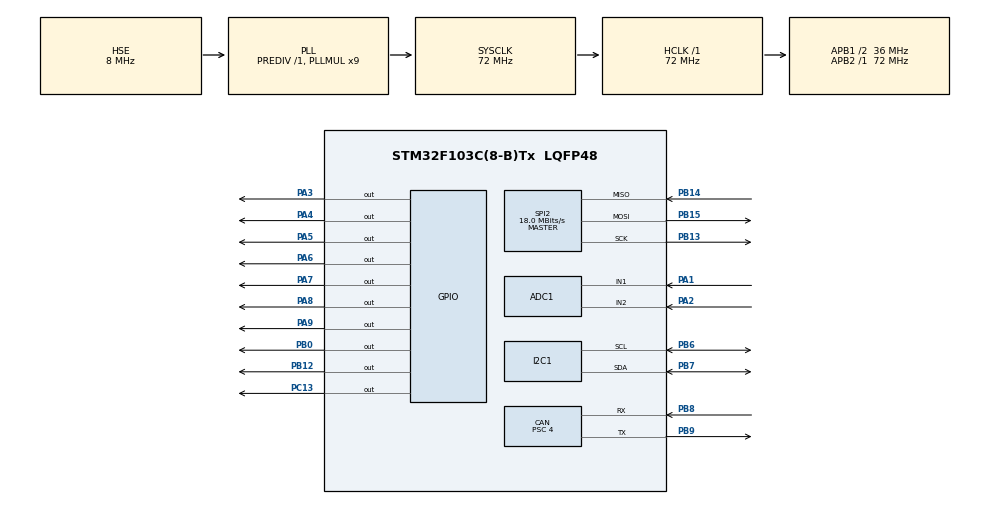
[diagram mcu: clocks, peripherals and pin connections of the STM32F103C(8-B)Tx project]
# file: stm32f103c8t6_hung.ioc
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ADC1.Channel-0\#ChannelRegularConversion=ADC_CHANNEL_1
ADC1.NbrOfConversionFlag=1
ADC1.Rank-0\#ChannelRegularConversion=1
ADC1.SamplingTime-0\#ChannelRegularConversion=ADC_SAMPLETIME_1CYCLE_5
ADC1.master=1
CAN.ABOM=ENABLE
CAN.AWUM=ENABLE
CAN.BS1=CAN_BS1_15TQ
CAN.BS2=CAN_BS2_2TQ
CAN.CalculateBaudRate=500000
CAN.CalculateTimeBit=2000
CAN.CalculateTimeQuantum=111.11111111111111
CAN.Prescaler=4
IWDG.Prescaler=IWDG_PRESCALER_64
IWDG.Reload=625
Mcu.Family=STM32F1
Mcu.Name=STM32F103C(8-B)Tx
Mcu.Package=LQFP48
NVIC.ADC1_2_IRQn=true\:0\:0\:false\:false\:true\:true\:true\:true
NVIC.PriorityGroup=NVIC_PRIORITYGROUP_4
NVIC.USB_LP_CAN1_RX0_IRQn=true\:0\:0\:false\:false\:true\:true\:true\:true
PA1.Signal=ADCx_IN1
PA13.Mode=Serial_Wire
PA13.Signal=SYS_JTMS-SWDIO
PA14.Mode=Serial_Wire
PA14.Signal=SYS_JTCK-SWCLK
PA2.Signal=ADCx_IN2
PA3.Signal=GPIO_Output
PA4.Signal=GPIO_Output
PA5.Signal=GPIO_Output
PA6.Signal=GPIO_Output
PA7.Signal=GPIO_Output
PA8.Signal=GPIO_Output
PA9.Signal=GPIO_Output
PB0.Signal=GPIO_Output
PB12.Signal=GPIO_Output
PB13.Mode=Full_Duplex_Master
PB13.Signal=SPI2_SCK
PB14.Mode=Full_Duplex_Master
PB14.Signal=SPI2_MISO
PB15.Mode=Full_Duplex_Master
PB15.Signal=SPI2_MOSI
PB6.Mode=I2C
PB6.Signal=I2C1_SCL
PB7.Mode=I2C
PB7.Signal=I2C1_SDA
PB8.GPIO_PuPd=GPIO_PULLUP
PB8.Mode=CAN_Activate
PB8.Signal=CAN_RX
PB9.Mode=CAN_Activate
PB9.Signal=CAN_TX
PC13-TAMPER-RTC.Signal=GPIO_Output
PC14-OSC32_IN.Mode=LSE-External-Oscillator
PC14-OSC32_IN.Signal=RCC_OSC32_IN
PC15-OSC32_OUT.Mode=LSE-External-Oscillator
PC15-OSC32_OUT.Signal=RCC_OSC32_OUT
PD0-OSC_IN.Mode=HSE-External-Oscillator
PD0-OSC_IN.Signal=RCC_OSC_IN
PD1-OSC_OUT.Mode=HSE-External-Oscillator
PD1-OSC_OUT.Signal=RCC_OSC_OUT
ProjectManager.HeapSize=0x200
ProjectManager.StackSize=0x400
ProjectManager.TargetToolchain=STM32CubeIDE
RCC.ADCPresc=RCC_ADCPCLK2_DIV6
RCC.AHBFreq_Value=72000000
RCC.APB1CLKDivider=RCC_HCLK_DIV2
RCC.APB1Freq_Value=36000000
RCC.APB1TimFreq_Value=72000000
RCC.APB2Freq_Value=72000000
RCC.APB2TimFreq_Value=72000000
RCC.HCLKFreq_Value=72000000
RCC.PLLMUL=RCC_PLL_MUL9
RCC.PLLSourceVirtual=RCC_PLLSOURCE_HSE
RCC.SYSCLKFreq_VALUE=72000000
RCC.SYSCLKSource=RCC_SYSCLKSOURCE_PLLCLK
RCC.USBFreq_Value=72000000
SH.ADCx_IN1.0=ADC1_IN1,IN1
SH.ADCx_IN2.0=ADC1_IN2,IN2
SPI2.CalculateBaudRate=18.0 MBits/s
SPI2.Direction=SPI_DIRECTION_2LINES
SPI2.Mode=SPI_MODE_MASTER
SPI2.VirtualType=VM_MASTER
VP_ADC1_TempSens_Input.Mode=IN-TempSens
VP_IWDG_VS_IWDG.Mode=IWDG_Activate
board=custom

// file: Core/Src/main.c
/* USER CODE BEGIN Header */
/* USER CODE END Header */
#include "main.h"
#include"i2c_drive.h"
#include <stdio.h>
#include<can_drive.h>
#include<uart_drive.h>
#include "mgr_com.h"
#include "il_para.h"
#include"drive_time.h"
#include "desc.h"
#include "W5500.h"
#include "modbus_common.h"
#include "spi.h"

ADC_HandleTypeDef hadc1;

CAN_HandleTypeDef hcan;

I2C_HandleTypeDef hi2c1;

IWDG_HandleTypeDef hiwdg;

SPI_HandleTypeDef hspi2;
static uint8_t version[2];

void SystemClock_Config(void);
static void MX_GPIO_Init(void);
static void MX_CAN_Init(void);
static void MX_I2C1_Init(void);
static void MX_ADC1_Init(void);
static void MX_IWDG_Init(void);
static void MX_SPI2_Init(void);

int main(void)
{

  /* MCU Configuration--------------------------------------------------------*/

  /* Reset of all peripherals, Initializes the Flash interface and the Systick. */
  HAL_Init();

  /* Configure the system clock */
  SystemClock_Config();

    /* Initialize all configured peripherals */
  	MX_GPIO_Init();
  	CAN1->MCR &= ~CAN_MCR_SLEEP;  // Đảm bảo CAN không ở chế độ Sleep
  	CAN1->MCR |= CAN_MCR_RESET;  // Reset CAN1
  	while (CAN1->MCR & CAN_MCR_RESET);  // Chờ Reset hoàn thành
  	RCC->APB1RSTR |=RCC_APB1RSTR_TIM2RST;//RESET TIMER 2
  	RCC->APB1RSTR &= ~RCC_APB1RSTR_TIM2RST;
  	RCC->APB1ENR |=RCC_APB1ENR_TIM2EN;
  	MX_CAN_Init(); //ok
  	Dest_Init();   //ok
  	MX_I2C1_Init();
  	//MX_TIM3_Init();
  	RCC->APB1ENR &= ~(1<<18);  // Tắt Clock UART3
  	RCC->APB2ENR |= (1<<18);   // Bật lại Clock UART3
  	USART3->CR1 |= (1<<13);  // Bật UART1
  	Uart_Init();
  	MX_ADC1_Init();
  	Timer2_Init();
  	Timer3_Init();
  	MX_IWDG_Init(); //watch dog
  	MX_SPI2_Init();
  	/* USER CODE BEGIN 2 */
  	//Uart_Init();
  /* USER CODE END 2 */
  	#ifdef CAN_RECEIVE_ALL_ID
  	{
  		  FillterConfig();
  	}
  	#else
  	{
  		  FillterConfigAll();
  	}
  	#endif
  	HAL_CAN_ActivateNotification(&hcan,CAN_IT_RX_FIFO0_MSG_PENDING); ////ok
  	CanInit(); //ok

  	ModbusCommon_Init();
  	settimer();
  	reset_timer();
  	Delay_SetTimer(TID_TIMER_1ms,2);
  	Delay_SetTimer(TID_COUNT_10ms,10);
  	Delay_SetTimer(TID_TIMER_1000ms,1000);
  	Clear_Infor_Can();
  	HAL_GPIO_WritePin(GPIOB, GPIO_PIN_12, 1);// reset
  	HAL_Delay(1);
  	initw5500();
  	settimer();

    /* Infinite loop */
    while (1)
    {
  	  if(Delay_GetTimer(TID_TIMER_1ms))
  	  {
  		HAL_IWDG_Refresh(&hiwdg);      // "Đá" watchdog để tránh reset
		if (update_status==StartUpDate)
  		{
  			Update_FW_ComTask();
  		}
  		else
  		{
  			if(Delay_GetTimer(TID_TIMER_1000ms))//1s
  			{
  				GPIOC->ODR ^=(1<<13);
  				gettime();
  				Task_LED_UV();
  				PutTimeRtc(version[0]);
  			}
  			Com_Task();
  		}
  	  }
      /* USER CODE BEGIN 3 */
    }
    /* Infinite loop */
    /* USER CODE BEGIN WHILE */
      /* USER CODE END WHILE */

      /* USER CODE BEGIN 3 */
    /* USER CODE END 3 */
  }

void SystemClock_Config(void)
{
  RCC_OscInitTypeDef RCC_OscInitStruct = {0};
  RCC_ClkInitTypeDef RCC_ClkInitStruct = {0};
  RCC_PeriphCLKInitTypeDef PeriphClkInit = {0};

  /** Initializes the RCC Oscillators according to the specified parameters
  * in the RCC_OscInitTypeDef structure.
  */
  RCC_OscInitStruct.OscillatorType = RCC_OSCILLATORTYPE_LSI|RCC_OSCILLATORTYPE_HSE;
  RCC_OscInitStruct.HSEState = RCC_HSE_ON;
  RCC_OscInitStruct.HSEPredivValue = RCC_HSE_PREDIV_DIV1;
  RCC_OscInitStruct.HSIState = RCC_HSI_ON;
  RCC_OscInitStruct.LSIState = RCC_LSI_ON;
  RCC_OscInitStruct.PLL.PLLState = RCC_PLL_ON;
  RCC_OscInitStruct.PLL.PLLSource = RCC_PLLSOURCE_HSE;
  RCC_OscInitStruct.PLL.PLLMUL = RCC_PLL_MUL9;
  if (HAL_RCC_OscConfig(&RCC_OscInitStruct) != HAL_OK)
  {
    Error_Handler();
  }

  /** Initializes the CPU, AHB and APB buses clocks
  */
  RCC_ClkInitStruct.ClockType = RCC_CLOCKTYPE_HCLK|RCC_CLOCKTYPE_SYSCLK
                              |RCC_CLOCKTYPE_PCLK1|RCC_CLOCKTYPE_PCLK2;
  RCC_ClkInitStruct.SYSCLKSource = RCC_SYSCLKSOURCE_PLLCLK;
  RCC_ClkInitStruct.AHBCLKDivider = RCC_SYSCLK_DIV1;
  RCC_ClkInitStruct.APB1CLKDivider = RCC_HCLK_DIV2;
  RCC_ClkInitStruct.APB2CLKDivider = RCC_HCLK_DIV1;

  if (HAL_RCC_ClockConfig(&RCC_ClkInitStruct, FLASH_LATENCY_2) != HAL_OK)
  {
    Error_Handler();
  }
  PeriphClkInit.PeriphClockSelection = RCC_PERIPHCLK_ADC;
  PeriphClkInit.AdcClockSelection = RCC_ADCPCLK2_DIV6;
  if (HAL_RCCEx_PeriphCLKConfig(&PeriphClkInit) != HAL_OK)
  {
    Error_Handler();
  }
}

static void MX_ADC1_Init(void)
{

  ADC_ChannelConfTypeDef sConfig = {0};

  /** Common config
  */
  hadc1.Instance = ADC1;
  hadc1.Init.ScanConvMode = ADC_SCAN_DISABLE;
  hadc1.Init.ContinuousConvMode = DISABLE;
  hadc1.Init.DiscontinuousConvMode = DISABLE;
  hadc1.Init.ExternalTrigConv = ADC_SOFTWARE_START;
  hadc1.Init.DataAlign = ADC_DATAALIGN_RIGHT;
  hadc1.Init.NbrOfConversion = 1;
  if (HAL_ADC_Init(&hadc1) != HAL_OK)
  {
    Error_Handler();
  }

  /** Configure Regular Channel
  */
  sConfig.Channel = ADC_CHANNEL_1;
  sConfig.Rank = ADC_REGULAR_RANK_1;
  sConfig.SamplingTime = ADC_SAMPLETIME_1CYCLE_5;
  if (HAL_ADC_ConfigChannel(&hadc1, &sConfig) != HAL_OK)
  {
    Error_Handler();
  }

}

static void MX_CAN_Init(void)
{

  hcan.Instance = CAN1;
  hcan.Init.Prescaler = 4;
  hcan.Init.Mode = CAN_MODE_NORMAL;
  hcan.Init.SyncJumpWidth = CAN_SJW_1TQ;
  hcan.Init.TimeSeg1 = CAN_BS1_15TQ;
  hcan.Init.TimeSeg2 = CAN_BS2_2TQ;
  hcan.Init.TimeTriggeredMode = DISABLE;
  hcan.Init.AutoBusOff = ENABLE;
  hcan.Init.AutoWakeUp = ENABLE;
  hcan.Init.AutoRetransmission = DISABLE;
  hcan.Init.ReceiveFifoLocked = DISABLE;
  hcan.Init.TransmitFifoPriority = DISABLE;
  if (HAL_CAN_Init(&hcan) != HAL_OK)
  {
    Error_Handler();
  }

}

static void MX_I2C1_Init(void)
{

  hi2c1.Instance = I2C1;
  hi2c1.Init.ClockSpeed = 100000;
  hi2c1.Init.DutyCycle = I2C_DUTYCYCLE_2;
  hi2c1.Init.OwnAddress1 = 0;
  hi2c1.Init.AddressingMode = I2C_ADDRESSINGMODE_7BIT;
  hi2c1.Init.DualAddressMode = I2C_DUALADDRESS_DISABLE;
  hi2c1.Init.OwnAddress2 = 0;
  hi2c1.Init.GeneralCallMode = I2C_GENERALCALL_DISABLE;
  hi2c1.Init.NoStretchMode = I2C_NOSTRETCH_DISABLE;
  if (HAL_I2C_Init(&hi2c1) != HAL_OK)
  {
    Error_Handler();
  }

}

static void MX_IWDG_Init(void)
{

  hiwdg.Instance = IWDG;
  hiwdg.Init.Prescaler = IWDG_PRESCALER_64;
  hiwdg.Init.Reload = 625;
  if (HAL_IWDG_Init(&hiwdg) != HAL_OK)
  {
    Error_Handler();
  }

}

static void MX_SPI2_Init(void)
{

  /* SPI2 parameter configuration*/
  hspi2.Instance = SPI2;
  hspi2.Init.Mode = SPI_MODE_MASTER;
  hspi2.Init.Direction = SPI_DIRECTION_2LINES;
  hspi2.Init.DataSize = SPI_DATASIZE_8BIT;
  hspi2.Init.CLKPolarity = SPI_POLARITY_LOW;
  hspi2.Init.CLKPhase = SPI_PHASE_1EDGE;
  hspi2.Init.NSS = SPI_NSS_SOFT;
  hspi2.Init.BaudRatePrescaler = SPI_BAUDRATEPRESCALER_2;
  hspi2.Init.FirstBit = SPI_FIRSTBIT_MSB;
  hspi2.Init.TIMode = SPI_TIMODE_DISABLE;
  hspi2.Init.CRCCalculation = SPI_CRCCALCULATION_DISABLE;
  hspi2.Init.CRCPolynomial = 10;
  if (HAL_SPI_Init(&hspi2) != HAL_OK)
  {
    Error_Handler();
  }

}

static void MX_GPIO_Init(void)
{
  GPIO_InitTypeDef GPIO_InitStruct = {0};

  /* GPIO Ports Clock Enable */
  __HAL_RCC_GPIOC_CLK_ENABLE();
  __HAL_RCC_GPIOD_CLK_ENABLE();
  __HAL_RCC_GPIOA_CLK_ENABLE();
  __HAL_RCC_GPIOB_CLK_ENABLE();

  /*Configure GPIO pin Output Level */
  HAL_GPIO_WritePin(GPIOC, GPIO_PIN_13, GPIO_PIN_RESET);

  /*Configure GPIO pin Output Level */
  HAL_GPIO_WritePin(GPIOA, GPIO_PIN_3|GPIO_PIN_4|GPIO_PIN_5|GPIO_PIN_6
                          |GPIO_PIN_7|GPIO_PIN_8|GPIO_PIN_9, GPIO_PIN_RESET);

  /*Configure GPIO pin Output Level */
  HAL_GPIO_WritePin(GPIOB, GPIO_PIN_0|GPIO_PIN_12, GPIO_PIN_RESET);

  /*Configure GPIO pin : PC13 */
  GPIO_InitStruct.Pin = GPIO_PIN_13;
  GPIO_InitStruct.Mode = GPIO_MODE_OUTPUT_PP;
  GPIO_InitStruct.Pull = GPIO_NOPULL;
  GPIO_InitStruct.Speed = GPIO_SPEED_FREQ_LOW;
  HAL_GPIO_Init(GPIOC, &GPIO_InitStruct);

  /*Configure GPIO pins : PA3 PA4 PA5 PA6
                           PA7 PA8 PA9 */
  GPIO_InitStruct.Pin = GPIO_PIN_3|GPIO_PIN_4|GPIO_PIN_5|GPIO_PIN_6
                          |GPIO_PIN_7|GPIO_PIN_8|GPIO_PIN_9;
  GPIO_InitStruct.Mode = GPIO_MODE_OUTPUT_PP;
  GPIO_InitStruct.Pull = GPIO_NOPULL;
  GPIO_InitStruct.Speed = GPIO_SPEED_FREQ_LOW;
  HAL_GPIO_Init(GPIOA, &GPIO_InitStruct);

  /*Configure GPIO pins : PB0 PB12 */
  GPIO_InitStruct.Pin = GPIO_PIN_0|GPIO_PIN_12;
  GPIO_InitStruct.Mode = GPIO_MODE_OUTPUT_PP;
  GPIO_InitStruct.Pull = GPIO_NOPULL;
  GPIO_InitStruct.Speed = GPIO_SPEED_FREQ_LOW;
  HAL_GPIO_Init(GPIOB, &GPIO_InitStruct);

}

void Error_Handler(void)
{
}
